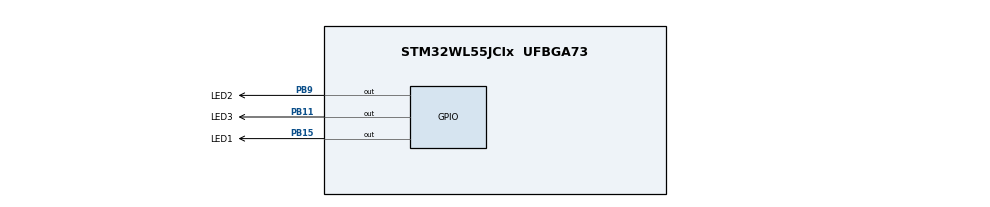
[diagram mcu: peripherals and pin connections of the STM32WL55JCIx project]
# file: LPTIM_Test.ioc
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LPTIM1.ClockPrescaler=LPTIM_PRESCALER_DIV128
Mcu.Family=STM32WL
Mcu.Name=STM32WL55JCIx
Mcu.Package=UFBGA73
NVIC.LPTIM1_IRQn=true\:0\:0\:false\:false\:true\:true\:true\:true
NVIC.PriorityGroup=NVIC_PRIORITYGROUP_4
PB11.GPIO_Label=LED3
PB11.Signal=GPIO_Output
PB15.GPIO_Label=LED1
PB15.Signal=GPIO_Output
PB9.GPIO_Label=LED2
PB9.Signal=GPIO_Output
ProjectManager.HeapSize=0x200
ProjectManager.StackSize=0x400
ProjectManager.TargetToolchain=STM32CubeIDE
RCC.AHBFreq_Value=32000000
RCC.APB1Freq_Value=32000000
RCC.APB1TimFreq_Value=32000000
RCC.APB2Freq_Value=32000000
RCC.APB2TimFreq_Value=32000000
RCC.APB3Freq_Value=32000000
RCC.CortexFreq_Value=32000000
RCC.HCLKFreq_Value=32000000
RCC.HSE_VALUE=8000000
RCC.HSI_VALUE=16000000
RCC.LPTIM1CLockSelection=RCC_LPTIM1CLKSOURCE_LSI
RCC.LSE_VALUE=32768
RCC.MSIClockRange=RCC_MSIRANGE_10
RCC.SYSCLKFreq_VALUE=32000000
RCC.VCOOutputFreq_Value=256000000
VP_LPTIM1_VS_LPTIM_counterModeInternalClock.Mode=Counts__internal_clock_event_00
board=custom

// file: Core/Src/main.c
/* USER CODE BEGIN Header */
/**
  ******************************************************************************
  * @file           : main.c
  * @brief          : Main program body
  ******************************************************************************
  * @attention
  *
  * Copyright (c) 2024 STMicroelectronics.
  * All rights reserved.
  *
  * This software is licensed under terms that can be found in the LICENSE file
  * in the root directory of this software component.
  * If no LICENSE file comes with this software, it is provided AS-IS.
  *
  ******************************************************************************
  */
/* USER CODE END Header */
#include "main.h"

LPTIM_HandleTypeDef hlptim1;

void SystemClock_Config(void);
static void MX_GPIO_Init(void);
static void MX_LPTIM1_Init(void);

int main(void)
{

  /* MCU Configuration--------------------------------------------------------*/

  /* Reset of all peripherals, Initializes the Flash interface and the Systick. */
  HAL_Init();

  /* Configure the system clock */
  SystemClock_Config();

  /* Initialize all configured peripherals */
  MX_GPIO_Init();
  MX_LPTIM1_Init();
  /* USER CODE BEGIN 2 */
  HAL_GPIO_WritePin(LED1_GPIO_Port, LED1_Pin, GPIO_PIN_SET);

  HAL_LPTIM_Counter_Start_IT(&hlptim1, (uint32_t)(5*32e6/128));

  /* USER CODE END 2 */

  /* Infinite loop */
  /* USER CODE BEGIN WHILE */
  while (1)
  {
	  HAL_GPIO_TogglePin(LED2_GPIO_Port, LED2_Pin);
    /* USER CODE END WHILE */
	  HAL_PWR_EnterSLEEPMode(PWR_MAINREGULATOR_ON, PWR_SLEEPENTRY_WFI);

  }
}

void SystemClock_Config(void)
{
  RCC_OscInitTypeDef RCC_OscInitStruct = {0};
  RCC_ClkInitTypeDef RCC_ClkInitStruct = {0};

  /** Configure the main internal regulator output voltage
  */
  __HAL_PWR_VOLTAGESCALING_CONFIG(PWR_REGULATOR_VOLTAGE_SCALE1);

  /** Initializes the CPU, AHB and APB buses clocks
  */
  RCC_OscInitStruct.OscillatorType = RCC_OSCILLATORTYPE_LSI|RCC_OSCILLATORTYPE_MSI;
  RCC_OscInitStruct.MSIState = RCC_MSI_ON;
  RCC_OscInitStruct.MSICalibrationValue = RCC_MSICALIBRATION_DEFAULT;
  RCC_OscInitStruct.MSIClockRange = RCC_MSIRANGE_10;
  RCC_OscInitStruct.LSIDiv = RCC_LSI_DIV1;
  RCC_OscInitStruct.LSIState = RCC_LSI_ON;
  RCC_OscInitStruct.PLL.PLLState = RCC_PLL_NONE;
  if (HAL_RCC_OscConfig(&RCC_OscInitStruct) != HAL_OK)
  {
    Error_Handler();
  }

  /** Configure the SYSCLKSource, HCLK, PCLK1 and PCLK2 clocks dividers
  */
  RCC_ClkInitStruct.ClockType = RCC_CLOCKTYPE_HCLK3|RCC_CLOCKTYPE_HCLK
                              |RCC_CLOCKTYPE_SYSCLK|RCC_CLOCKTYPE_PCLK1
                              |RCC_CLOCKTYPE_PCLK2;
  RCC_ClkInitStruct.SYSCLKSource = RCC_SYSCLKSOURCE_MSI;
  RCC_ClkInitStruct.AHBCLKDivider = RCC_SYSCLK_DIV1;
  RCC_ClkInitStruct.APB1CLKDivider = RCC_HCLK_DIV1;
  RCC_ClkInitStruct.APB2CLKDivider = RCC_HCLK_DIV1;
  RCC_ClkInitStruct.AHBCLK3Divider = RCC_SYSCLK_DIV1;

  if (HAL_RCC_ClockConfig(&RCC_ClkInitStruct, FLASH_LATENCY_1) != HAL_OK)
  {
    Error_Handler();
  }
}

static void MX_LPTIM1_Init(void)
{

  hlptim1.Instance = LPTIM1;
  hlptim1.Init.Clock.Source = LPTIM_CLOCKSOURCE_APBCLOCK_LPOSC;
  hlptim1.Init.Clock.Prescaler = LPTIM_PRESCALER_DIV128;
  hlptim1.Init.Trigger.Source = LPTIM_TRIGSOURCE_SOFTWARE;
  hlptim1.Init.OutputPolarity = LPTIM_OUTPUTPOLARITY_HIGH;
  hlptim1.Init.UpdateMode = LPTIM_UPDATE_IMMEDIATE;
  hlptim1.Init.CounterSource = LPTIM_COUNTERSOURCE_INTERNAL;
  hlptim1.Init.Input1Source = LPTIM_INPUT1SOURCE_GPIO;
  hlptim1.Init.Input2Source = LPTIM_INPUT2SOURCE_GPIO;
  if (HAL_LPTIM_Init(&hlptim1) != HAL_OK)
  {
    Error_Handler();
  }

}

static void MX_GPIO_Init(void)
{
  GPIO_InitTypeDef GPIO_InitStruct = {0};

  /* GPIO Ports Clock Enable */
  __HAL_RCC_GPIOB_CLK_ENABLE();

  /*Configure GPIO pin Output Level */
  HAL_GPIO_WritePin(GPIOB, LED1_Pin|LED2_Pin|LED3_Pin, GPIO_PIN_RESET);

  /*Configure GPIO pins : LED1_Pin LED2_Pin LED3_Pin */
  GPIO_InitStruct.Pin = LED1_Pin|LED2_Pin|LED3_Pin;
  GPIO_InitStruct.Mode = GPIO_MODE_OUTPUT_PP;
  GPIO_InitStruct.Pull = GPIO_NOPULL;
  GPIO_InitStruct.Speed = GPIO_SPEED_FREQ_LOW;
  HAL_GPIO_Init(GPIOB, &GPIO_InitStruct);

}

/* USER CODE BEGIN 4 */
void HAL_LPTIM_AutoReloadMatchCallback(LPTIM_HandleTypeDef* h) {
	HAL_GPIO_TogglePin(LED3_GPIO_Port, LED3_Pin);
}
/* USER CODE END 4 */

void Error_Handler(void)
{
  __disable_irq();
  while (1)
  {
  }
}
